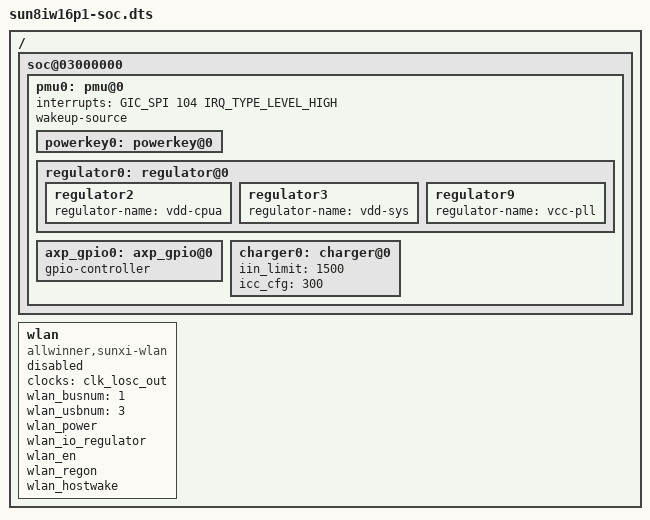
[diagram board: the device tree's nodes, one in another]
/*
 * Allwinner Technology CO., Ltd. sun8iw16p1 soc board.
 *
 * soc board support.
 */

/dts-v1/;

#include "sun8iw16p1.dtsi"

/{

	soc@03000000 {
		pmu0: pmu@0{
			interrupts = <GIC_SPI 104 IRQ_TYPE_LEVEL_HIGH>;
			status = "okay";
			wakeup-source;

			powerkey0: powerkey@0{
				status = "okay";
			};

			regulator0: regulator@0{
				status = "okay";

				regulator2 {
					regulator-name = "vdd-cpua";
				};

				regulator3 {
					regulator-name = "vdd-sys";
				};

				regulator9 {
					regulator-name = "vcc-pll";
				};

			};

			axp_gpio0: axp_gpio@0{
				gpio-controller;
				#size-cells = <0>;
				#gpio-cells = <6>;
				status = "okay";
			};

			charger0: charger@0{
				status = "okay";
				/* input current limit reg:0x16 */
				iin_limit = <1500>;
				/* const current charge current limit reg:0x62
				 */
				icc_cfg = <300>;
			};
		};
	};

	wlan:wlan {
		compatible = "allwinner,sunxi-wlan";
		clocks = <&clk_losc_out>;
		wlan_busnum = <1>;
		wlan_usbnum = <3>;
		wlan_power;
		wlan_io_regulator;
		wlan_en;
		wlan_regon;
		wlan_hostwake;
		status = "disabled";
	};
};
